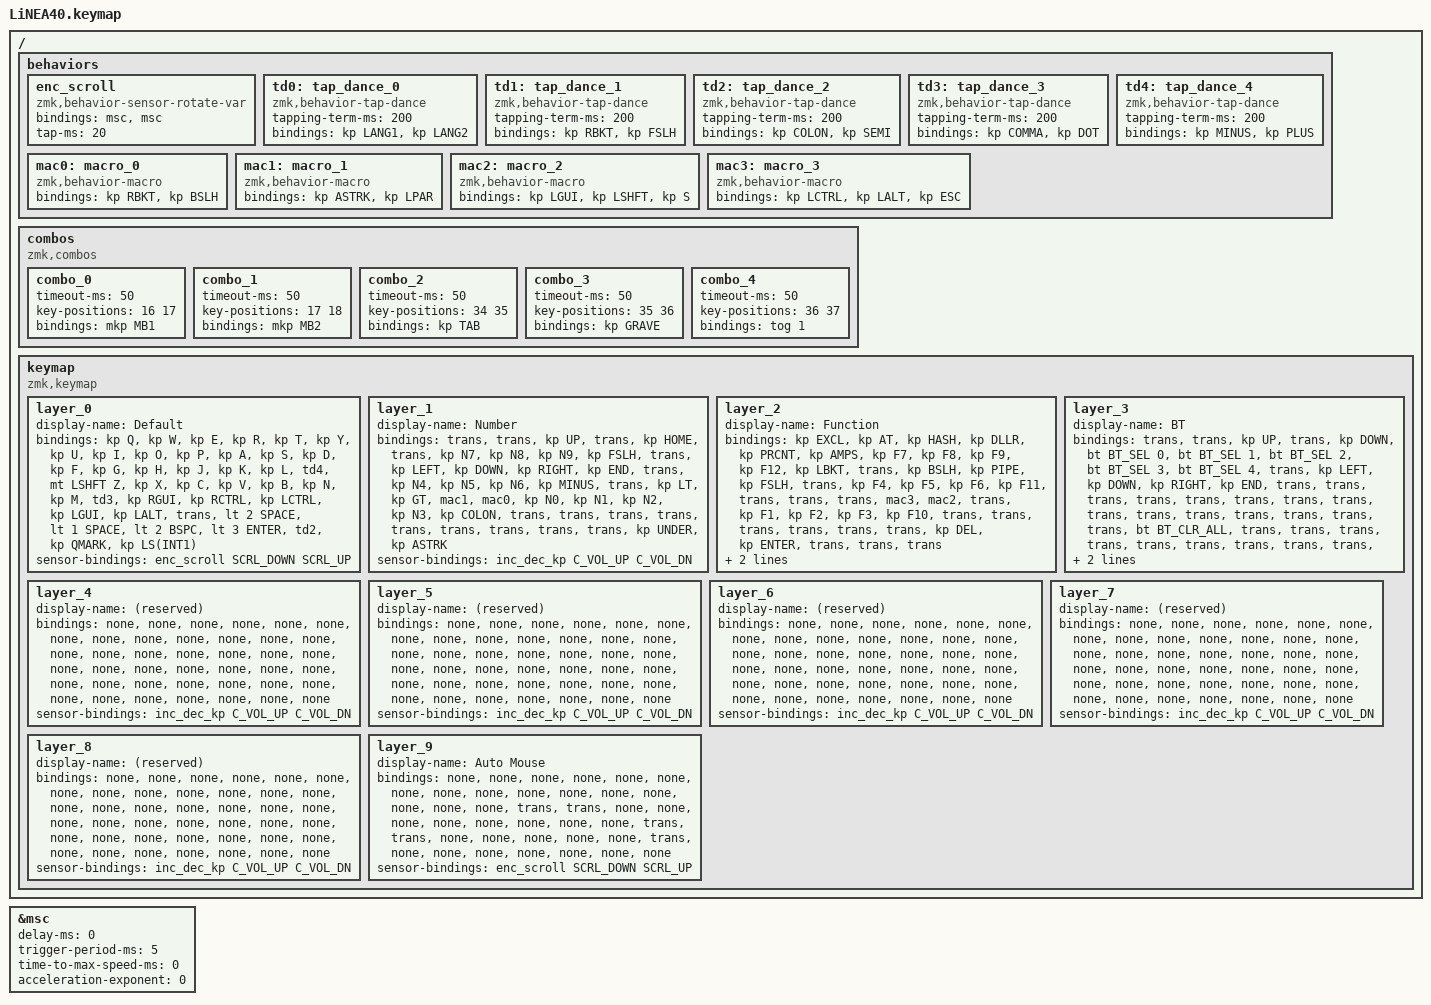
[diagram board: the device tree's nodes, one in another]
/*
 * LiNEA40 Keymap
 * Generated by LiNEA40 Configurator
 * 2026-10-16T08:23:16.454Z
 */

/* エンコーダー1目盛りで約1ティック分スクロールさせるための速度 */
#define ZMK_POINTING_DEFAULT_SCRL_VAL 60

#include <behaviors.dtsi>
#include <dt-bindings/zmk/keys.h>
#include <dt-bindings/zmk/bt.h>
#include <dt-bindings/zmk/mouse.h>
#include <dt-bindings/zmk/pointing.h>

#define DEFAULT 0
#define NUMBER 1
#define FUNCTION 2
#define BT 3
#define AUTO_MOUSE 9

/ {
    behaviors {
        enc_scroll: enc_scroll {
            compatible = "zmk,behavior-sensor-rotate-var";
            #sensor-binding-cells = <2>;
            bindings = <&msc>, <&msc>;
            tap-ms = <20>;
        };

        td0: tap_dance_0 {
            compatible = "zmk,behavior-tap-dance";
            #binding-cells = <0>;
            tapping-term-ms = <200>;
            bindings = <&kp LANG1>, <&kp LANG2>;
        };

        td1: tap_dance_1 {
            compatible = "zmk,behavior-tap-dance";
            #binding-cells = <0>;
            tapping-term-ms = <200>;
            bindings = <&kp RBKT>, <&kp FSLH>;
        };

        td2: tap_dance_2 {
            compatible = "zmk,behavior-tap-dance";
            #binding-cells = <0>;
            tapping-term-ms = <200>;
            bindings = <&kp COLON>, <&kp SEMI>;
        };

        td3: tap_dance_3 {
            compatible = "zmk,behavior-tap-dance";
            #binding-cells = <0>;
            tapping-term-ms = <200>;
            bindings = <&kp COMMA>, <&kp DOT>;
        };

        td4: tap_dance_4 {
            compatible = "zmk,behavior-tap-dance";
            #binding-cells = <0>;
            tapping-term-ms = <200>;
            bindings = <&kp MINUS>, <&kp PLUS>;
        };

        mac0: macro_0 {
            compatible = "zmk,behavior-macro";
            #binding-cells = <0>;
            bindings = <&kp RBKT>, <&kp BSLH>;
        };

        mac1: macro_1 {
            compatible = "zmk,behavior-macro";
            #binding-cells = <0>;
            bindings = <&kp ASTRK>, <&kp LPAR>;
        };

        mac2: macro_2 {
            compatible = "zmk,behavior-macro";
            #binding-cells = <0>;
            bindings = <&kp LGUI>, <&kp LSHFT>, <&kp S>;
        };

        mac3: macro_3 {
            compatible = "zmk,behavior-macro";
            #binding-cells = <0>;
            bindings = <&kp LCTRL>, <&kp LALT>, <&kp ESC>;
        };
    };

    combos {
        compatible = "zmk,combos";
        combo_0 {
            timeout-ms = <50>;
            key-positions = <16 17>;
            bindings = <&mkp MB1>;
        };

        combo_1 {
            timeout-ms = <50>;
            key-positions = <17 18>;
            bindings = <&mkp MB2>;
        };

        combo_2 {
            timeout-ms = <50>;
            key-positions = <34 35>;
            bindings = <&kp TAB>;
        };

        combo_3 {
            timeout-ms = <50>;
            key-positions = <35 36>;
            bindings = <&kp GRAVE>;
        };

        combo_4 {
            timeout-ms = <50>;
            key-positions = <36 37>;
            bindings = <&tog 1>;
        };
    };

    keymap {
        compatible = "zmk,keymap";

        layer_0 {
            display-name = "Default";
            bindings = <
                &kp Q
                &kp W
                &kp E
                &kp R
                &kp T
                &kp Y
                &kp U
                &kp I
                &kp O
                &kp P
                &kp A
                &kp S
                &kp D
                &kp F
                &kp G
                &kp H
                &kp J
                &kp K
                &kp L
                &td4
                &mt LSHFT Z
                &kp X
                &kp C
                &kp V
                &kp B
                &kp N
                &kp M
                &td3
                &kp RGUI
                &kp RCTRL
                &kp LCTRL
                &kp LGUI
                &kp LALT
                &trans
                &lt 2 SPACE
                &lt 1 SPACE
                &lt 2 BSPC
                &lt 3 ENTER
                &td2
                &kp QMARK
                &kp LS(INT1)
            >;
            sensor-bindings = <&enc_scroll SCRL_DOWN SCRL_UP>;
        };

        layer_1 {
            display-name = "Number";
            bindings = <
                &trans
                &trans
                &kp UP
                &trans
                &kp HOME
                &trans
                &kp N7
                &kp N8
                &kp N9
                &kp FSLH
                &trans
                &kp LEFT
                &kp DOWN
                &kp RIGHT
                &kp END
                &trans
                &kp N4
                &kp N5
                &kp N6
                &kp MINUS
                &trans
                &kp LT
                &kp GT
                &mac1
                &mac0
                &kp N0
                &kp N1
                &kp N2
                &kp N3
                &kp COLON
                &trans
                &trans
                &trans
                &trans
                &trans
                &trans
                &trans
                &trans
                &trans
                &kp UNDER
                &kp ASTRK
            >;
            sensor-bindings = <&inc_dec_kp C_VOL_UP C_VOL_DN>;
        };

        layer_2 {
            display-name = "Function";
            bindings = <
                &kp EXCL
                &kp AT
                &kp HASH
                &kp DLLR
                &kp PRCNT
                &kp AMPS
                &kp F7
                &kp F8
                &kp F9
                &kp F12
                &kp LBKT
                &trans
                &kp BSLH
                &kp PIPE
                &kp FSLH
                &trans
                &kp F4
                &kp F5
                &kp F6
                &kp F11
                &trans
                &trans
                &trans
                &mac3
                &mac2
                &trans
                &kp F1
                &kp F2
                &kp F3
                &kp F10
                &trans
                &trans
                &trans
                &trans
                &trans
                &trans
                &kp DEL
                &kp ENTER
                &trans
                &trans
                &trans
            >;
            sensor-bindings = <&enc_scroll SCRL_RIGHT SCRL_LEFT>;
        };

        layer_3 {
            display-name = "BT";
            bindings = <
                &trans
                &trans
                &kp UP
                &trans
                &kp DOWN
                &bt BT_SEL 0
                &bt BT_SEL 1
                &bt BT_SEL 2
                &bt BT_SEL 3
                &bt BT_SEL 4
                &trans
                &kp LEFT
                &kp DOWN
                &kp RIGHT
                &kp END
                &trans
                &trans
                &trans
                &trans
                &trans
                &trans
                &trans
                &trans
                &trans
                &trans
                &trans
                &trans
                &trans
                &trans
                &trans
                &bt BT_CLR_ALL
                &trans
                &trans
                &trans
                &trans
                &trans
                &trans
                &trans
                &trans
                &trans
                &trans
            >;
            sensor-bindings = <&inc_dec_kp C_BRI_UP C_BRI_DN>;
        };

        layer_4 {
            display-name = "(reserved)";
            bindings = <
                &none
                &none
                &none
                &none
                &none
                &none
                &none
                &none
                &none
                &none
                &none
                &none
                &none
                &none
                &none
                &none
                &none
                &none
                &none
                &none
                &none
                &none
                &none
                &none
                &none
                &none
                &none
                &none
                &none
                &none
                &none
                &none
                &none
                &none
                &none
                &none
                &none
                &none
                &none
                &none
                &none
            >;
            sensor-bindings = <&inc_dec_kp C_VOL_UP C_VOL_DN>;
        };

        layer_5 {
            display-name = "(reserved)";
            bindings = <
                &none
                &none
                &none
                &none
                &none
                &none
                &none
                &none
                &none
                &none
                &none
                &none
                &none
                &none
                &none
                &none
                &none
                &none
                &none
                &none
                &none
                &none
                &none
                &none
                &none
                &none
                &none
                &none
                &none
                &none
                &none
                &none
                &none
                &none
                &none
                &none
                &none
                &none
                &none
                &none
                &none
            >;
            sensor-bindings = <&inc_dec_kp C_VOL_UP C_VOL_DN>;
        };

        layer_6 {
            display-name = "(reserved)";
            bindings = <
                &none
                &none
                &none
                &none
                &none
                &none
                &none
                &none
                &none
                &none
                &none
                &none
                &none
                &none
                &none
                &none
                &none
                &none
                &none
                &none
                &none
                &none
                &none
                &none
                &none
                &none
                &none
                &none
                &none
                &none
                &none
                &none
                &none
                &none
                &none
                &none
                &none
                &none
                &none
                &none
                &none
            >;
            sensor-bindings = <&inc_dec_kp C_VOL_UP C_VOL_DN>;
        };

        layer_7 {
            display-name = "(reserved)";
            bindings = <
                &none
                &none
                &none
                &none
                &none
                &none
                &none
                &none
                &none
                &none
                &none
                &none
                &none
                &none
                &none
                &none
                &none
                &none
                &none
                &none
                &none
                &none
                &none
                &none
                &none
                &none
                &none
                &none
                &none
                &none
                &none
                &none
                &none
                &none
                &none
                &none
                &none
                &none
                &none
                &none
                &none
            >;
            sensor-bindings = <&inc_dec_kp C_VOL_UP C_VOL_DN>;
        };

        layer_8 {
            display-name = "(reserved)";
            bindings = <
                &none
                &none
                &none
                &none
                &none
                &none
                &none
                &none
                &none
                &none
                &none
                &none
                &none
                &none
                &none
                &none
                &none
                &none
                &none
                &none
                &none
                &none
                &none
                &none
                &none
                &none
                &none
                &none
                &none
                &none
                &none
                &none
                &none
                &none
                &none
                &none
                &none
                &none
                &none
                &none
                &none
            >;
            sensor-bindings = <&inc_dec_kp C_VOL_UP C_VOL_DN>;
        };

        layer_9 {
            display-name = "Auto Mouse";
            bindings = <
                &none
                &none
                &none
                &none
                &none
                &none
                &none
                &none
                &none
                &none
                &none
                &none
                &none
                &none
                &none
                &none
                &trans
                &trans
                &none
                &none
                &none
                &none
                &none
                &none
                &none
                &none
                &trans
                &trans
                &none
                &none
                &none
                &none
                &none
                &trans
                &none
                &none
                &none
                &none
                &none
                &none
                &none
            >;
            sensor-bindings = <&enc_scroll SCRL_DOWN SCRL_UP>;
        };
    };
};

&msc {
    delay-ms = <0>;
    trigger-period-ms = <5>;
    time-to-max-speed-ms = <0>;
    acceleration-exponent = <0>;
};
